# nrf7120E_enga_application register map
Vendor: Nordic Semiconductor; Series: nrf71; File version: 1
CPU: CM33 r0p4, little endian, MPU, FPU, 3 interrupt priority bits, 270 interrupts, 4 SAU regions
Registers are 32-bit, read-write, reset 0x0 unless marked. A register's access mark holds for its fields unless they carry their own. Offsets are from the block's base; [hi:lo] are bit positions; lines under a group give offsets from that group; {n}, {i} and the like mark numbered series; 'fields as' and 'values as' point back to an identical list.

## GLOBAL_WICR_NS — Wi-Fi Information Configuration Registers
Base 0x003FD000
0x00 FIRMWARE group — Unspecified
  0x00 LMACINITPC reset 0x28080000 — Boot address for LMAC processor (defaults to start of Wi-Fi core ROM_0)
    [31:0] INITPC — LMAC boot vector
  0x04 UMACINITPC reset 0x28180000 — Boot address for UMAC processor (defaults to start of Wi-Fi core ROM_1)
    [31:0] INITPC — UMAC boot vector
  0x08 LMACROMPATCHADDR — Address in MRAM for LMAC ROM patch
    [31:0] Address — LMAC ROM patch address
  0x0C UMACROMPATCHADDR — Address in MRAM for UMAC ROM patch
    [31:0] Address — UMAC ROM patch address
0x80 IPCCONFIG group — Unspecified
  0x00 COMMANDMBOXADDR — Base address of command mailbox
    [31:0] ADDRESS — Base address of mailbox
  0x04 COMMANDMBOXSIZE — Size of command mailbox in bytes
    [31:0] SIZE — Size in bytes
  0x08 EVENTMBOXADDR — Base address of event mailbox
    [31:0] ADDRESS — Base address of mailbox
  0x0C EVENTMBOXSIZE — Size of event mailbox in bytes
    [31:0] SIZE — Size in bytes
  0x10 SPAREMBOXADDR — Base address of spare mailbox
    [31:0] ADDRESS — Base address of mailbox
  0x14 SPAREMBOXSIZE — Size of spare mailbox in bytes
    [31:0] SIZE — Size in bytes
0x100 VTFDATA reset 0xFFFFFFFF — Pointer to memory location containing VTF data from the VTF monitoring system
  [31:0] ADDRESS — Address of the VTF monitoring data in RAM
0x104 RFPARAMSDATAADDR — Base address of RF parameter data
  [31:0] ADDRESS
0x108 RFPARAMSDATASIZE — Size of RF parameter data in bytes
  [31:0] SIZE — Size in bytes

## ICACHE_S — Cache
Base 0xE0082000
0x08 TASKS_INVALIDATECACHE wo — Invalidate the cache.
  [0] TASKS_INVALIDATECACHE
    1=Trigger task
0x400 STATUS ro — Status of the cache activities.
  [0] READY — Ready status.
    0=Ready (Activity is done and ready for the next activity.); 1=Busy (Activity is in progress.)
0x404 ENABLE — Enable cache.
  [0] ENABLE — Enable cache
    0=Disabled (Disable cache); 1=Enabled (Enable cache)
0x414 PROFILING group — Unspecified
  0x00 ENABLE — Enable the profiling counters.
    [0] ENABLE — Enable the profiling counters
      0=Disable profiling; 1=Enable profiling
  0x04 CLEAR wo — Clear the profiling counters.
    [0] CLEAR — Clearing the profiling counters
      1=Clear the profiling counters
  0x08 HIT ro — The cache hit counter for cache region.
    [31:0] HITS — Number of cache hits
  0x0C MISS ro — The cache miss counter for cache region.
    [31:0] MISSES — Number of cache misses

## SWI00_S — Software interrupt 0
Base 0x5001C000
Same registers: SWI01_S 0x5001D000, SWI02_S 0x5001E000, SWI03_S 0x5001F000

## GLOBAL_DPPIC00_NS — Distributed programmable peripheral interconnect controller 0
Base 0x40042000; alternate view of GLOBAL_USBHSCORE_NS
Same registers: GLOBAL_DPPIC10_NS 0x40082000, GLOBAL_DPPIC20_NS 0x400C2000, GLOBAL_DPPIC30_NS 0x40102000, GLOBAL_DPPIC00_S 0x50042000 (alternate view of GLOBAL_USBHSCORE_S), GLOBAL_DPPIC10_S 0x50082000, GLOBAL_DPPIC20_S 0x500C2000, GLOBAL_DPPIC30_S 0x50102000
{0x0+8i} TASKS_CHG[{i}] (i=0..5) group — Channel group tasks
  0x00 EN wo — Description cluster: Enable channel group n
    [0] EN — Enable channel group n
      1=Trigger task
  0x04 DIS wo — Description cluster: Disable channel group n
    [0] DIS — Disable channel group n
      1=Trigger task
{0x80+8i} SUBSCRIBE_CHG[{i}] (i=0..5) group — Subscribe configuration for tasks
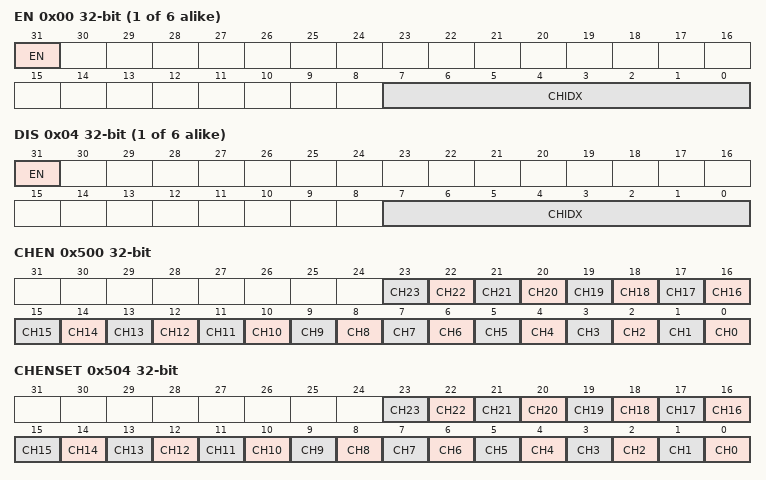
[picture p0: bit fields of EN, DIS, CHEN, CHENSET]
  0x00 EN — Description cluster: Subscribe configuration for task CHG[n].EN
    [31] EN
      0=Disabled (Disable subscription); 1=Enabled (Enable subscription)
    [7:0] CHIDX — DPPI channel that task CHG[n].EN will subscribe to
  0x04 DIS — Description cluster: Subscribe configuration for task CHG[n].DIS
    [31] EN
      values as SUBSCRIBE_CHG[0].EN.EN
    [7:0] CHIDX — DPPI channel that task CHG[n].DIS will subscribe to
0x500 CHEN — Channel enable register
  [all] fields
    0=Disabled (Disable channel); 1=Enabled (Enable channel)
  [n] CH{n} (n=0..23) — Enable or disable channel {n}
0x504 CHENSET write-1-sets — Channel enable set register
  [all] fields
    on read: 0=Disabled (Read: Channel disabled); 1=Enabled (Read: Channel enabled) | on write: 1=Set (Write: Enable channel)
  [n] CH{n} (n=0..23) — Channel {n} enable set register. Writing 0 has no effect.
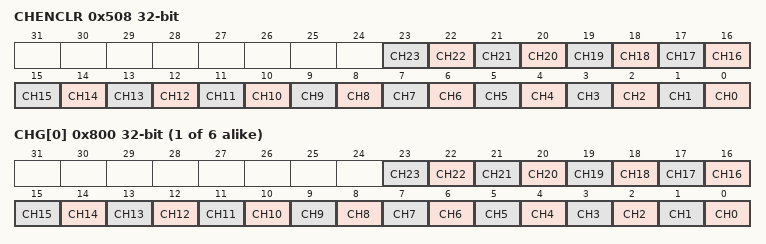
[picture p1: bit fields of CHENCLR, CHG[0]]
0x508 CHENCLR write-1-clears — Channel enable clear register
  [all] fields
    on read: 0=Disabled (Read: Channel disabled); 1=Enabled (Read: Channel enabled) | on write: 1=Clear (Write: Disable channel)
  [n] CH{n} (n=0..23) — Channel {n} enable clear register. Writing 0 has no effect.
{0x800+4i} CHG[{i}] (i=0..5) — Description collection: Channel group n Note: Writes to this register are ignored if either SUBSCRIBE_CHG[n].EN or SUBSCRIBE_CHG[n].DIS is enabled
  [all] fields
    0=Excluded; 1=Included
  [n] CH{n} (n=0..23) — Include or exclude channel {n}
